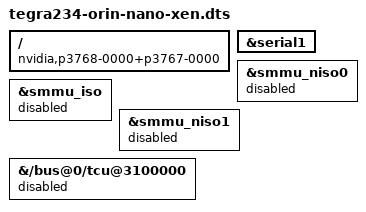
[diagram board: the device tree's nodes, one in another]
/dts-v1/;
/plugin/;

/ {
    compatible = "nvidia,p3768-0000+p3767-0000", "nvidia,tegra234";
    fragment@0 {
        target = <&serial1>;    /* /bus@0/serial@3100000 = hsuart0 */
        __overlay__ {
            /delete-property/ resets;
            /delete-property/ reset-names;
            status = "okay";
        };
    };

    /* ----------------------------------------------------------------
     * Fragment 1-3: Disable all three SMMU instances
     *
     * With iommu=no / smmu=no in xen.cfg, Xen does not initialise
     * SMMU hardware. If Dom0 Linux probes arm-smmu-v3 on these nodes
     * while the hardware is in an unknown state, it will hang or fault
     * during Dom0 boot. Disable them here.
     *
     * When you are ready to enable SMMU passthrough:
     *   1. Set Xen options: smmu=yes iommu=yes
     *   2. Change these back to status = "okay"
     *   3. Rebuild and reflash
     *
     * Three SMMU instances on Tegra234:
     *   smmu_niso0  0x08000000  General DMA (bpmp, aon, host1x)
     *   smmu_iso    0x10000000  Isochronous (camera, display)
     *   smmu_niso1  0x12000000  High-BW (GPU, PCIe, NVMe)
     * ---------------------------------------------------------------- */
    
    fragment@1 {
        target = <&smmu_niso0>;
        __overlay__ {
            status = "disabled";
        };
    };

    fragment@2 {
        target = <&smmu_iso>;
        __overlay__ {
            status = "disabled";
        };
    };

    fragment@3 {
        target = <&smmu_niso1>;
        __overlay__ {
            status = "disabled";
        };
    };

    fragment@4 {
        target-path = "/bus@0/tcu@3100000";
        __overlay__ {
            status = "disabled";
        };
    };
};
